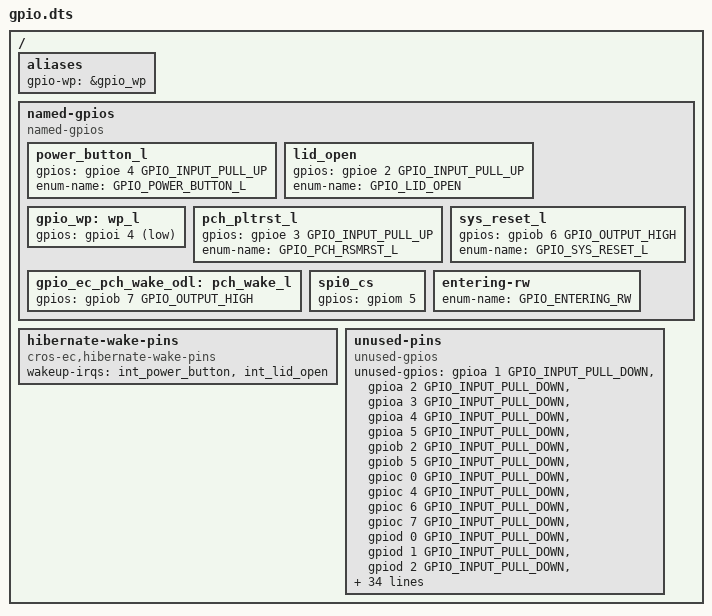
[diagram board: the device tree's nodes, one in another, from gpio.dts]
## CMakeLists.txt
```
# Copyright 2021 The ChromiumOS Authors
# Use of this source code is governed by a BSD-style license that can be
# found in the LICENSE file.

cmake_minimum_required(VERSION 3.13.1)

find_package(Zephyr REQUIRED HINTS "${ZEPHYR_BASE}")
project(it8xxx2_evb)

# Include board specific header files
zephyr_include_directories(include)

zephyr_library_sources_ifndef(CONFIG_I2C_TARGET "src/i2c_test.c")
zephyr_library_sources_ifdef(CONFIG_I2C_TARGET "src/i2c_ite_target_cb.c")
zephyr_library_sources_ifdef(CONFIG_I2C_TARGET "src/board.c")
```

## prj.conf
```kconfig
# Copyright 2021 The ChromiumOS Authors
# Use of this source code is governed by a BSD-style license that can be
# found in the LICENSE file.

CONFIG_CROS_EC=y
CONFIG_PLATFORM_EC=y

# SoC configuration
CONFIG_AP=y
CONFIG_AP_ARM_MTK_MT8192=y

# Lid switch
CONFIG_PLATFORM_EC_LID_SWITCH=y

# I2C channel A and C swapping
CONFIG_I2C_IT8XXX2_SWAP_CHA_CHC=y

# Power Button
CONFIG_PLATFORM_EC_POWER_BUTTON=y

# TODO(b:185202623): bring these features up
CONFIG_PLATFORM_EC_BACKLIGHT_LID=n
CONFIG_PLATFORM_EC_BOARD_VERSION_CBI=n
CONFIG_PLATFORM_EC_BOARD_VERSION_GPIO=n
CONFIG_PLATFORM_EC_KEYBOARD=n
CONFIG_PLATFORM_EC_SWITCH=n
CONFIG_PLATFORM_EC_VBOOT_EFS2=n
CONFIG_PLATFORM_EC_VBOOT_HASH=n

# USB-C
CONFIG_PLATFORM_EC_USB_PD_TBT_COMPAT_MODE=n
CONFIG_PLATFORM_EC_USB_PD_USB4=n
```

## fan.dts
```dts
/* Copyright 2022 The ChromiumOS Authors
 * Use of this source code is governed by a BSD-style license that can be
 * found in the LICENSE file.
 */

/ {
	fans {
		compatible = "cros-ec,fans";

		fan_0 {
			pwms = <&pwm7 PWM_CHANNEL_7 PWM_KHZ(30) PWM_POLARITY_NORMAL>;
			tach = <&tach0>;
			rpm_min = <1500>;
			rpm_start = <1500>;
			rpm_max = <6500>;
		};
	};
};

/* fan tachometer sensor */
&tach0 {
	status = "disabled";
	channel = <IT8XXX2_TACH_CHANNEL_A>;
	pulses-per-round = <2>;
	pinctrl-0 = <&tach0a_gpd6_default>;
	pinctrl-names = "default";
};
```

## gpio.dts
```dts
/* Copyright 2022 The ChromiumOS Authors
 * Use of this source code is governed by a BSD-style license that can be
 * found in the LICENSE file.
 */

#include <dt-bindings/gpio_defines.h>

/ {
	aliases {
		gpio-wp = &gpio_wp;
	};

	named-gpios {
		compatible = "named-gpios";

		power_button_l: power_button_l {
			gpios = <&gpioe 4 GPIO_INPUT_PULL_UP>;
			enum-name = "GPIO_POWER_BUTTON_L";
		};
		lid_open: lid_open {
			gpios = <&gpioe 2 GPIO_INPUT_PULL_UP>;
			enum-name = "GPIO_LID_OPEN";
		};
		gpio_wp: wp_l {
			gpios = <&gpioi 4 (GPIO_INPUT_PULL_UP |
					   GPIO_ACTIVE_LOW)>;
		};
		pch_pltrst_l {
			gpios = <&gpioe 3 GPIO_INPUT_PULL_UP>;
			enum-name = "GPIO_PCH_RSMRST_L";
		};
		sys_reset_l {
			gpios = <&gpiob 6 GPIO_OUTPUT_HIGH>;
			enum-name = "GPIO_SYS_RESET_L";
		};
		gpio_ec_pch_wake_odl: pch_wake_l {
			gpios = <&gpiob 7 GPIO_OUTPUT_HIGH>;
		};
		spi0_cs: spi0_cs {
			gpios = <&gpiom 5 (GPIO_INPUT | GPIO_VOLTAGE_1P8)>;
		};
		/* unimplemented GPIOs */
		entering-rw {
			enum-name = "GPIO_ENTERING_RW";
		};
	};

	hibernate-wake-pins {
		compatible = "cros-ec,hibernate-wake-pins";
		wakeup-irqs = <&int_power_button
			       &int_lid_open>;
	};

	unused-pins {
		compatible = "unused-gpios";

		unused-gpios =
			/* gpioa1 */
			<&gpioa 1 GPIO_INPUT_PULL_DOWN>,
			/* gpioa2 */
			<&gpioa 2 GPIO_INPUT_PULL_DOWN>,
			/* gpioa3 */
			<&gpioa 3 GPIO_INPUT_PULL_DOWN>,
			/* gpioa4 */
			<&gpioa 4 GPIO_INPUT_PULL_DOWN>,
			/* gpioa5 */
			<&gpioa 5 GPIO_INPUT_PULL_DOWN>,

			/* gpiob2 */
			<&gpiob 2 GPIO_INPUT_PULL_DOWN>,
			/* gpiob5 */
			<&gpiob 5 GPIO_INPUT_PULL_DOWN>,

			/* gpioc0 */
			<&gpioc 0 GPIO_INPUT_PULL_DOWN>,
			/* gpioc4 */
			<&gpioc 4 GPIO_INPUT_PULL_DOWN>,
			/* gpioc6 */
			<&gpioc 6 GPIO_INPUT_PULL_DOWN>,
			/* gpioc7 */
			<&gpioc 7 GPIO_INPUT_PULL_DOWN>,

			/* gpiod0 */
			<&gpiod 0 GPIO_INPUT_PULL_DOWN>,
			/* gpiod1 */
			<&gpiod 1 GPIO_INPUT_PULL_DOWN>,
			/* gpiod2 */
			<&gpiod 2 GPIO_INPUT_PULL_DOWN>,
			/* gpiod3 */
			<&gpiod 3 GPIO_INPUT_PULL_DOWN>,
			/* gpiod4 */
			<&gpiod 4 GPIO_INPUT_PULL_DOWN>,
			/* gpiod5 */
			<&gpiod 5 GPIO_INPUT_PULL_DOWN>,
			/* gpiod7 */
			<&gpiod 7 GPIO_INPUT_PULL_DOWN>,

			/* gpioe1 */
			<&gpioe 1 GPIO_INPUT_PULL_DOWN>,
			/* gpioe5 */
			<&gpioe 5 GPIO_INPUT_PULL_DOWN>,
			/* gpioe6 */
			<&gpioe 6 GPIO_INPUT_PULL_DOWN>,

			/* gpiof0 */
			<&gpiof 0 GPIO_INPUT_PULL_DOWN>,
			/* gpiof1 */
			<&gpiof 1 GPIO_INPUT_PULL_DOWN>,
			/* gpiof2 */
			<&gpiof 2 GPIO_INPUT_PULL_DOWN>,
			/* gpiof3 */
			<&gpiof 3 GPIO_INPUT_PULL_DOWN>,
			/* gpiof4 */
			<&gpiof 4 GPIO_INPUT_PULL_DOWN>,
			/* gpiof5 */
			<&gpiof 5 GPIO_INPUT_PULL_DOWN>,

			/* gpiog1 */
			<&gpiog 1 GPIO_INPUT_PULL_DOWN>,
			/* gpiog6 */
			<&gpiog 6 GPIO_INPUT_PULL_UP>,

			/* gpioh0 */
			<&gpioh 0 GPIO_INPUT_PULL_DOWN>,
			/* gpioh3 */
			<&gpioh 3 GPIO_INPUT_PULL_DOWN>,
			/* gpioh4 */
			<&gpioh 4 GPIO_INPUT_PULL_DOWN>,

			/* gpioi6 */
			<&gpioi 6 GPIO_INPUT_PULL_DOWN>,
			/* gpioi7 */
			<&gpioi 7 GPIO_INPUT_PULL_DOWN>,

			/* gpioj0 */
			<&gpioj 0 GPIO_INPUT_PULL_DOWN>,
			/* gpioj1 */
			<&gpioj 1 GPIO_INPUT_PULL_DOWN>,
			/* gpioj2 */
			<&gpioj 2 GPIO_INPUT_PULL_DOWN>,
			/* gpioj3 */
			<&gpioj 3 GPIO_INPUT_PULL_DOWN>,
			/* gpioj4 */
			<&gpioj 4 GPIO_INPUT_PULL_DOWN>,
			/* gpioj5 */
			<&gpioj 5 GPIO_INPUT_PULL_DOWN>,
			/* gpioj6 */
			<&gpioj 6 GPIO_OUTPUT_LOW>,
			/* gpioj7 */
			<&gpioj 7 GPIO_OUTPUT_LOW>,

			/* gpiom0 */
			<&gpiom 0 GPIO_INPUT_PULL_DOWN>,
			/* gpiom1 */
			<&gpiom 1 GPIO_INPUT_PULL_DOWN>,
			/* gpiom2 */
			<&gpiom 2 GPIO_INPUT_PULL_DOWN>,
			/* gpiom3 */
			<&gpiom 3 GPIO_INPUT_PULL_DOWN>,
			/* gpiom4 */
			<&gpiom 4 GPIO_INPUT_PULL_DOWN>,
			/* gpiom6 */
			<&gpiom 6 GPIO_INPUT_PULL_DOWN>;
	};
};
```

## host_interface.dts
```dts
/* Copyright 2022 The Chromium OS Authors. All rights reserved.
 * Use of this source code is governed by a BSD-style license that can be
 * found in the LICENSE file.
 */

/* host interface */
/ {
	chosen {
		zephyr,ec-host-interface = &shi0;
	};
};

&shi0 {
	status = "okay";
	cs-gpios = <&gpiom 5 IT8XXX2_GPIO_VOLTAGE_1P8>;
	pinctrl-0 = <&shi_mosi_gpm0_default
		&shi_miso_gpm1_default
		&shi_clk_gpm4_default
		&shi_cs_gpm5_default>;
	pinctrl-names = "default";
};
```

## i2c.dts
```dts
/* Copyright 2022 The ChromiumOS Authors
 * Use of this source code is governed by a BSD-style license that can be
 * found in the LICENSE file.
 */

/ {
	named-i2c-ports {
		compatible = "named-i2c-ports";

		battery {
			i2c-port = <&i2c2>;
			enum-names = "I2C_PORT_BATTERY";
		};
		evb-1 {
			i2c-port = <&i2c0>;
			enum-names = "I2C_PORT_EVB_1";
		};
		evb-2 {
			i2c-port = <&i2c1>;
			enum-names = "I2C_PORT_EVB_2";
		};
		opt-4 {
			i2c-port = <&i2c4>;
			enum-names = "I2C_PORT_OPT_4";
		};
	};
};

&i2c0 {
	status = "okay";
	clock-frequency = <I2C_BITRATE_STANDARD>;
	pinctrl-0 = <&i2c2_clk_gpf6_default
		     &i2c2_data_gpf7_default>;
	pinctrl-names = "default";
	scl-gpios = <&gpiof 6 0>;
	sda-gpios = <&gpiof 7 0>;
};

&i2c1 {
	status = "okay";
	clock-frequency = <I2C_BITRATE_STANDARD>;
	pinctrl-0 = <&i2c1_clk_gpc1_default
		     &i2c1_data_gpc2_default>;
	pinctrl-names = "default";
};

&i2c2 {
	status = "okay";
	clock-frequency = <I2C_BITRATE_STANDARD>;
	pinctrl-0 = <&i2c0_clk_gpb3_default
		     &i2c0_data_gpb4_default>;
	pinctrl-names = "default";
	scl-gpios = <&gpiob 3 0>;
	sda-gpios = <&gpiob 4 0>;
};

&i2c4 {
	status = "okay";
	clock-frequency = <I2C_BITRATE_STANDARD>;
	pinctrl-0 = <&i2c4_clk_gpe0_default
		     &i2c4_data_gpe7_default>;
	pinctrl-names = "default";
};
```

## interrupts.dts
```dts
/* Copyright 2022 The ChromiumOS Authors
 * Use of this source code is governed by a BSD-style license that can be
 * found in the LICENSE file.
 */

/ {
	gpio-interrupts {
		compatible = "cros-ec,gpio-interrupts";

		int_power_button: power_button {
			irq-pin = <&power_button_l>;
			flags = <GPIO_INT_EDGE_BOTH>;
			handler = "power_button_interrupt";
		};
		int_lid_open: lid_open {
			irq-pin = <&lid_open>;
			flags = <GPIO_INT_EDGE_BOTH>;
			handler = "lid_interrupt";
		};
	};
};
```

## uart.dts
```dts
/* Copyright 2023 The ChromiumOS Authors
 * Use of this source code is governed by a BSD-style license that can be
 * found in the LICENSE file.
 */

&uart2 {
	status = "okay";
	current-speed = <460800>;
	clock-frequency = <1843200>;
};
&ite_uart2_wrapper {
	status = "okay";
	pinctrl-0 = <&uart2_rx_gph5_default
		     &uart2_tx_gph6_default>;
	pinctrl-names = "default";
	gpios = <&gpioh 5 0>;
};
```

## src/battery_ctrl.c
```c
/*
 * Copyright (c) 2026 ITE Corporation. All Rights Reserved.
 *
 * SPDX-License-Identifier: Apache-2.0
 */

#include "console.h"
#include "crc8.h"
#include "i2c.h"

#include <zephyr/drivers/i2c.h>

static int platform_ec_i2c_write_dma(const int port, const uint16_t addr_flags,
				 const uint8_t *out, int out_size)
{
	if (!IS_ENABLED(CONFIG_SMBUS_PEC) && I2C_USE_PEC(addr_flags))
		return EC_ERROR_UNIMPLEMENTED;

	if (IS_ENABLED(CONFIG_SMBUS_PEC)) {
		int i, rv;
		uint8_t addr_8bit = I2C_STRIP_FLAGS(addr_flags) << 1;
		uint8_t pec;

		pec = cros_crc8(&addr_8bit, 1);
		pec = cros_crc8_arg(out, out_size, pec);

		i2c_lock(port, 1);
		for (i = 0; i <= CONFIG_I2C_NACK_RETRY_COUNT; i++) {

			uint8_t tx_buf[out_size + 1];
			int tx_len = sizeof(tx_buf);

			memcpy(tx_buf, out, out_size);
			tx_buf[out_size] = pec;

			rv = i2c_xfer_unlocked(port, addr_flags, tx_buf, tx_len,
					       NULL, 0, I2C_XFER_START | I2C_XFER_STOP);

			if (!rv)
				break;

		}
		i2c_lock(port, 0);

		return rv;
	}

	return i2c_xfer(port, addr_flags, out, out_size, NULL, 0);
}

int i2c_write16_dma(const int port, const uint16_t addr_flags, int offset, int data)
{
	uint8_t buf[1 + sizeof(uint16_t)];

	buf[0] = offset & 0xff;
	buf[1] = (data >> 8) & 0xff;
	buf[2] = data & 0xff;

	return platform_ec_i2c_write_dma(port, addr_flags, buf,
					 1 + sizeof(uint16_t));
}
```

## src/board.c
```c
/*
 * Copyright (c) 2025 ITE Corporation. All Rights Reserved.
 *
 * SPDX-License-Identifier: Apache-2.0
 */

#include <zephyr/drivers/i2c.h>
#include <zephyr/drivers/pinctrl.h>
#include <zephyr/init.h>
#include <ap_power/ap_power.h>
#include "console.h"

#define I2C5_TARGET DT_NODELABEL(i2c5_target)
#define I2C5_NODE DT_BUS(I2C5_TARGET)
PINCTRL_DT_DEFINE(I2C5_NODE);
const struct device *i2c_target = DEVICE_DT_GET(I2C5_TARGET);

static int command_pin_input_pulldown(int argc, const char **argv)
{
	const struct pinctrl_dev_config *pcfg = PINCTRL_DT_DEV_CONFIG_GET(I2C5_NODE);

	if (!strcmp(argv[1], "1")) {
		pinctrl_apply_state(pcfg, PINCTRL_STATE_DEFAULT);
	} else if (!strcmp(argv[1], "0")) {
		pinctrl_apply_state(pcfg, PINCTRL_STATE_SLEEP);
	}

	return 0;
}
DECLARE_SAFE_CONSOLE_COMMAND(pininput, command_pin_input_pulldown, NULL, "Setting pin input pulldown");

static void board_suspend_handler(struct ap_power_ev_callback *cb, struct ap_power_ev_data data)
{

	switch (data.event) {
	default:
		return;

	case AP_POWER_STARTUP:

		i2c_target_driver_register(i2c_target);
		break;

	case AP_POWER_HARD_OFF:

		i2c_target_driver_unregister(i2c_target);
		break;
	}
}

static int install_suspend_handler(void)
{
	static struct ap_power_ev_callback cb;

	/*
	 * Add a callback for suspend/resume.
	 */
	ap_power_ev_init_callback(&cb, board_suspend_handler, AP_POWER_RESUME | AP_POWER_SUSPEND);
	ap_power_ev_add_callback(&cb);

	/* Register I2C target */
	i2c_target_driver_register(i2c_target);

	return 0;
}

SYS_INIT(install_suspend_handler, APPLICATION, 1);
```

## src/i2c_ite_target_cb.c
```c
/*
 * Copyright (c) 2023 ITE Corporation. All Rights Reserved.
 *
 * SPDX-License-Identifier: Apache-2.0
 */

#define DT_DRV_COMPAT ite_target_i2c

#include <zephyr/drivers/gpio.h>
#include <zephyr/drivers/i2c.h>
#include <zephyr/drivers/pinctrl.h>
#include <zephyr/irq.h>
#include <zephyr/kernel.h>
#include <zephyr/pm/policy.h>
#include <errno.h>
#include <soc.h>
#include <soc_dt.h>
#include <zephyr/sys/util.h>

#include <zephyr/logging/log.h>
LOG_MODULE_REGISTER(i2c_ite_target, 4);

struct i2c_target_dev_config {
	/* I2C alternate configuration */
	struct i2c_dt_spec bus;
};

struct i2c_target_data {
	struct i2c_target_config config;
	uint32_t buffer_idx;
	uint8_t w_buffer[256];
	uint8_t r_buffer[256];
	uint8_t first_write;
};

static int i2c_ite_target_write_requested(struct i2c_target_config *config)
{
	struct i2c_target_data *data = CONTAINER_OF(config,
						struct i2c_target_data,
						config);

	LOG_DBG("[target]: write req");

	data->first_write = true;

	return 0;
}

static int i2c_ite_target_read_requested(struct i2c_target_config *config,
					 uint8_t *val)
{
	struct i2c_target_data *data = CONTAINER_OF(config,
						struct i2c_target_data,
						config);



	*val = data->r_buffer[data->buffer_idx++];
	//LOG_DBG("[target]: read req: *val=%x",*val);
	return 0;
}

static int i2c_ite_target_write_received(struct i2c_target_config *config,
					 uint8_t val)
{
	struct i2c_target_data *data = CONTAINER_OF(config,
						    struct i2c_target_data,
						    config);

	if (data->first_write) {
		//LOG_DBG("[target]target_write_received: val=%x",val);
		data->first_write = false;
	} else {
		data->w_buffer[data->buffer_idx++] = val;
	}

	return 0;
}

static int i2c_ite_target_read_processed(struct i2c_target_config *config,
					 uint8_t *val)
{
	struct i2c_target_data *data = CONTAINER_OF(config,
						    struct i2c_target_data,
						    config);

	*val = data->r_buffer[data->buffer_idx++];

	//LOG_DBG("[target]target_read_processed: read done, val=0x%x", *val);

	return 0;
}

static int i2c_ite_target_stop(struct i2c_target_config *config)
{
	struct i2c_target_data *data = CONTAINER_OF(config,
						    struct i2c_target_data,
						    config);

	//LOG_DBG("[target]: stop");
	//k_busy_wait(1500);
	data->buffer_idx = 0;
	data->first_write = true;

	return 0;
}

#ifdef CONFIG_I2C_TARGET_BUFFER_MODE
static void i2c_ite_target_buf_write_received(struct i2c_target_config *config,
					      uint8_t *ptr, uint32_t len)
{
	//LOG_DBG("[target]: w-ptr=%p, len=%d", ptr, len);
}
static int i2c_ite_target_buf_read_requested(struct i2c_target_config *config,
					     uint8_t **ptr, uint32_t *len)
{
	struct i2c_target_data *data = CONTAINER_OF(config,
						struct i2c_target_data,
						config);

	*len = sizeof(data->r_buffer);
	*ptr = data->r_buffer;

	//LOG_DBG("[target]: r-ptr=%p, len=%d", *ptr,*len);

	return 0;
}
#endif

static const struct i2c_target_callbacks target_callbacks = {
	.write_requested = i2c_ite_target_write_requested,
	.read_requested = i2c_ite_target_read_requested,
	.write_received = i2c_ite_target_write_received,
	.read_processed = i2c_ite_target_read_processed,
#ifdef CONFIG_I2C_TARGET_BUFFER_MODE
	.buf_write_received = i2c_ite_target_buf_write_received,
	.buf_read_requested = i2c_ite_target_buf_read_requested,
#endif
	.stop = i2c_ite_target_stop,
};

static int i2c_ite_target_register(const struct device *dev)
{
	const struct i2c_target_dev_config *cfg = dev->config;
	struct i2c_target_data *data = dev->data;

	LOG_DBG("[target]i2c target register");

	return i2c_target_register(cfg->bus.bus, &data->config);
}

static int i2c_ite_target_unregister(const struct device *dev)
{
	const struct i2c_target_dev_config *cfg = dev->config;
	struct i2c_target_data *data = dev->data;

	LOG_DBG("[target]i2c target unregister");

	return i2c_target_unregister(cfg->bus.bus, &data->config);
}

static const struct i2c_target_driver_api api_funcs = {
	.driver_register = i2c_ite_target_register,
	.driver_unregister = i2c_ite_target_unregister,
};

static int i2c_ite_target_init(const struct device *dev)
{
	const struct i2c_target_dev_config *cfg = dev->config;
	struct i2c_target_data *data = dev->data;

	//LOG_DBG("[target]i2c_target_init i2c target bus=%p",cfg->bus.bus); //I2C5 node
	//LOG_DBG("[target]i2c_target_init i2c target dev=%p",dev); //I2C target
	//LOG_DBG("[target]i2c_target_init i2c target data config=%p",&data->config);

	/* Check I2C controller ready. */
	if (!device_is_ready(cfg->bus.bus)) {
		LOG_ERR("I2C controller device not ready");
		return -ENODEV;
	}

	data->config.address = cfg->bus.addr;
	data->config.callbacks = &target_callbacks;

	LOG_DBG("[target]w_buffer=%p",data->w_buffer);
	LOG_DBG("[target]r_buffer=%p",data->r_buffer);

	for (int i = 0; i < 256; i++) {
		data->r_buffer[i] = 255-i;
	}


	return 0;
}

#define I2C_ITE_TARGET_INIT(inst)                                               \
	static const struct i2c_target_dev_config i2c_target_cfg_##inst = {     \
		.bus = I2C_DT_SPEC_INST_GET(inst),			        \
	};                                                                      \
										\
	static struct i2c_target_data i2c_target_data_##inst;                   \
										\
	I2C_DEVICE_DT_INST_DEFINE(inst, i2c_ite_target_init,                    \
				  NULL,                                         \
				  &i2c_target_data_##inst,                      \
				  &i2c_target_cfg_##inst,                       \
				  POST_KERNEL,                                  \
				  CONFIG_I2C_TARGET_INIT_PRIORITY,              \
				  &api_funcs);                                  \

DT_INST_FOREACH_STATUS_OKAY(I2C_ITE_TARGET_INIT)
```

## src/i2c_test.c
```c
/* Copyright 2023 The ChromiumOS Authors
 * Use of this source code is governed by a BSD-style license that can be
 * found in the LICENSE file.
 */

#include "hooks.h"
#include "task.h"
#include "i2c.h"

#include <zephyr/kernel.h>
#include <zephyr/device.h>
#include <zephyr/devicetree.h>
#include <zephyr/drivers/i2c.h>
#include <zephyr/sys/printk.h>

//#define I2C_DEV_NODE	DT_ALIAS(i2c_1)
#define I2C_DEV_NODE	DT_NODELABEL(i2c4)

uint32_t i2c_cfg = I2C_SPEED_SET(I2C_SPEED_STANDARD) | I2C_MODE_CONTROLLER;
uint8_t w_datas[255];
uint8_t r_datas[255];
uint8_t w_datas1[59];
uint8_t r_datas1[64];

static int test_i2c_host(const struct device *const i2c_dev)
{
#if 0
	printf("\n[main]1.===read datas===\n");

	if (i2c_read(i2c_dev, r_datas, sizeof(r_datas), 0x52)) {
		printf("Fail to read\n");
		return -1;
	}

	printf("\n[main]===read second===\n");

	if (i2c_read(i2c_dev, r_datas, sizeof(r_datas), 0x62)) {
		printf("Fail to read\n");
		return -1;
	}


	printf("[main]1.===write datas(<=255bytes FIFO mode allowed)===\n");

	for (int i = 0; i < sizeof(w_datas); i++) {
		w_datas[i] = i;
	}
	//w_datas[256]=0x77;w_datas[257]=0x78;w_datas[258]=0x79;

	if (i2c_write(i2c_dev, w_datas, sizeof(w_datas), 0x52)) {
		printf("Fail to write\n");
		return -1;
	}


#endif
	//printf("\n[main]1-1.===write datas(<=59bytes CQ mode allowed)===\n");
#if 1
	if (i2c_write(i2c_dev, w_datas1, sizeof(w_datas1), 0x52)) {
		printf("Fail to write\n");
		return -1;
	}

	//printf("\n[main]2.===read datas(<=255bytes FIFO mode allowed)===\n");

	if (i2c_read(i2c_dev, r_datas1, sizeof(r_datas1), 0x52)) {
		printf("Fail to read\n");
		return -1;
	}

	w_datas1[0] = 0x22;
	w_datas1[1] = 0x00;

	int ret2 = i2c_write(i2c_dev, w_datas, sizeof(w_datas), 0x52);
	if (ret2) {
		printf("Fail to write = ret=%d\n",ret2);
		return -1;
	}

	ret2 = i2c_read(i2c_dev, r_datas, sizeof(r_datas), 0x52);
	if (ret2) {
		printf("Fail to read ret = %d\n",ret2);
		return -1;
	}
	printf("raw data: %x %x %x %x %x %x %x %x\n",
				r_datas[0], r_datas[1], r_datas[2],
				r_datas[3], r_datas[4], r_datas[5], r_datas[6], r_datas[6]);


	printf("\n[main]3.===i2c_burst_read(<=255bytes FIFO mode allowed)===\n");

	(void)memset(&r_datas, 0, sizeof(r_datas));

	if (i2c_burst_read(i2c_dev, 0x52, 0xaa, r_datas, sizeof(r_datas))) {
		printf("Fail to read\n");
		return -1;
	}
	printf("axis raw data: %x %x %x %x %x %x\n",
				r_datas[0], r_datas[1], r_datas[2],
				r_datas[3], r_datas[4], r_datas[5]);
#endif
#if 0
	//printf("\n[main]3-1.===i2c_burst_read(<=64bytes CQ mode allowed)===\n");

	if (i2c_burst_read(i2c_dev, 0x52, 0xaa, r_datas1, sizeof(r_datas1))) {
		printf("Fail to read\n");
		return -1;
	}
	//printf("axis raw data: %x %x %x %x %x %x\n",
	//			r_datas1[0], r_datas1[1], r_datas1[2],
	//			r_datas1[3], r_datas1[4], r_datas1[5]);

#endif
#if 0
	printf("\n[main]4.===i2c_burst_write(CQ and FIFO mode don't allow)===\n");

	if (i2c_burst_write(i2c_dev, 0x52, 0xbb, w_datas, sizeof(w_datas)-1)) {
		printk("Fail to write\n");
		return -1;
	}

	printf("\n[main]5.===Cros I2C: i2c_read_block(<=255bytes FIFO mode allowed)===\n");

	(void)memset(&r_datas, 0, sizeof(r_datas));

	if (i2c_read_block(1,0x52,0xcc,r_datas,sizeof(r_datas))) { //i2c_1-->port=1, i2c_4-->port=3
		printf("Fail to read\n");
		return -1;
	}
	printk("[i2c]axis raw data: %x %x %x %x %x %x\n",
				r_datas[0], r_datas[1], r_datas[2],
				r_datas[3], r_datas[4], r_datas[5]);


	printf("\n[main]6.===Cros I2C: i2c_write_block(CQ and FIFO mode don't allow)===\n");

	if (i2c_write_block(1,0x52,0xdd,w_datas,sizeof(w_datas)-1)) {
		printk("Fail to write\n");
		return -1;
	}
#endif

#ifdef CONFIG_PLATFORM_EC_SMBUS_PEC
	/* I2C4 = number of enable port = 3th */
	if (i2c_write16(3, 0x52, 0xbb, 0xccdd)) {
		printf("Fail to write\n");
		return -1;
	}
#endif

	return 0;
}

static void board_init(void)
{
	int ret;
	timestamp_t t_i2chost_start, t_i2chost_end;
	uint64_t duration_us;
	const struct device *const i2c_dev = DEVICE_DT_GET(I2C_DEV_NODE);
	uint32_t i2c_cfg_tmp;

	printf("[main]===test_i2c_host to target===\n");

	if (!device_is_ready(i2c_dev)) {
		printf("I2C device is not ready\n");
		return;
	}

	/* 1. Verify i2c_configure() */
	if (i2c_configure(i2c_dev, i2c_cfg)) {
		printf("I2C config failed\n");
		return;
	}

	/* 2. Verify i2c_get_config() */
	if (i2c_get_config(i2c_dev, &i2c_cfg_tmp)) {
		printf("I2C get_config failed\n");
		return;
	}
	if (i2c_cfg != i2c_cfg_tmp) {
		printf("I2C get_config returned invalid config\n");
		return;
	}

	for (int i = 0; i < sizeof(w_datas); i++) {
		w_datas[i] = i;
	}
	for (int i = 0; i < sizeof(w_datas1); i++) {
		w_datas1[i] = i;
	}

	t_i2chost_start = get_time();
	for(int i=0; i<1; i++) {
		ret = test_i2c_host(i2c_dev);
		//k_sleep(K_MSEC(1));
	}
	t_i2chost_end = get_time();

	duration_us = (t_i2chost_end.val - t_i2chost_start.val);
	printk("i2c host total duration_us %llu us\n", duration_us);

	if(ret)
		printf("[main]fail to access\n");
	else
		printf("[main]i2c transfer sucess!\n\n\n");

}
DECLARE_HOOK(HOOK_INIT, board_init, HOOK_PRIO_POST_I2C);
```
